# PIC32MX440F128L device description
Architecture: MIPS; Family: PIC32MX; Series: PIC32MX
Registers are 32-bit, read-write, no defined reset value unless marked. A register's access mark holds for its fields unless they carry their own. Offsets are from the block's base; [hi:lo] are bit positions; 'fields as' and 'values as' point back to an identical list.

## SPI
Instances: SPI 0x1f8057f4 in periph0
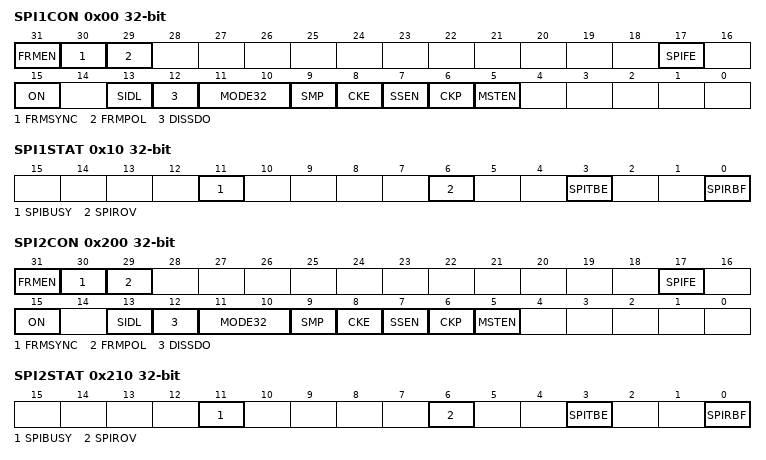
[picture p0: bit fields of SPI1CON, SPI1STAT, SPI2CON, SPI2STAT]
0x00 SPI1CON — SPI Control Register
  [31] FRMEN — Framed SPI Support bit
    1=Framed SPI support is enabled (SSx pin used as FSYNC input/output); 0=Framed SPI support is disabled
  [30] FRMSYNC — Frame Sync Pulse Direction Control on SSx pin bit (Framed SPI mode only)
    1=Frame sync pulse input (Slave mode); 0=Frame sync pulse output (Master mode)
  [29] FRMPOL — Frame Sync Polarity bit (Framed SPI mode only)
    1=Frame pulse is active-high; 0=Frame pulse is active-low
  [17] SPIFE — Frame Sync Pulse Edge Select bit
    1=Frame synchronization pulse coincides with the first bit clock; 0=Frame synchronization pulse precedes the first bit clock
  [15] ON — SPI Peripheral On bit
    1=SPI Peripheral is enabled; 0=SPI Peripheral is disabled
  [13] SIDL — Stop in Idle Mode bit
    1=Discontinue operation when CPU enters in Idle mode; 0=Continue operation in Idle mode
  [12] DISSDO — Disable SDOx pin bit
    1=SDOx pin is not used by the module. Pin is controlled by associated PORT register; 0=SDOx pin is controlled by the module
  [11:10] MODE32 — 32/16-Bit Communication Select bits
    3=(AUDEN=1) 24-bit Data, 32-bit FIFO, 32-bit Channel/64-bit Frame / (AUDEN=0) 32-bit communication; 2=(AUDEN=1) 32-bit Data, 32-bit FIFO, 32-bit Channel/64-bit Frame / (AUDEN=0) 32-bit communication; 1=(AUDEN=1) 16-bit Data, 16-bit FIFO, 32-bit Channel/64-bit Frame / (AUDEN=0) 16-bit communication; 0=(AUDEN=1) 16-bit Data, 16-bit FIFO, 16-bit Channel/32-bit Frame / (AUDEN=0) 8-bit communication
  [9] SMP — SPI Data Input Sample Phase bit (master mode only)
    1=(Master mode) Input data sampled at end of data output time / (Slave mode) value is ignored; 0=(Master mode) Input data sampled at middle of data output time / (Slave mode) value is ignored
  [8] CKE — SPI Clock Edge Select bit
    1=Serial output data changes on transition from active clock state to Idle clock state (see CKP bit); 0=Serial output data changes on transition from Idle clock state to active clock state (see CKP bit)
  [7] SSEN — Slave Select Enable bit
    1=SSx pin used for Slave mode; 0=SSx pin not used for Slave mode
  [6] CKP — Clock Polarity Select bit
    1=Idle state for clock is a high level; active state is a low level; 0=Idle state for clock is a low level; active state is a high level
  [5] MSTEN — Master Mode Enable bit
    1=Master mode; 0=Slave mode
0x10 SPI1STAT ro
  [11] SPIBUSY — SPI Activity Status bit
    1=SPI peripheral is currently busy with some transactions; 0=SPI peripheral is currently idle
  [6] SPIROV — Receive Overflow Flag bit
    1=A new data is completely received and discarded. The user software has not read the previous data in the SPIxBUF register.; 0=No overflow has occurred
  [3] SPITBE — SPI Transmit Buffer Empty Status bit
    1=Transmit buffer SPIxTXB is empty; 0=Transmit buffer SPIxTXB is not empty
  [0] SPIRBF — SPI Receive Buffer Full Status bit
    1=Receive buffer SPIxRXB is full; 0=Receive buffer SPIxRXB is not full
0x20 SPI1BUF
0x30 SPI1BRG
  [8:0] SPI1BRG
0x200 SPI2CON — SPI Control Register
  fields as SPI1CON
0x210 SPI2STAT ro
  fields as SPI1STAT
0x220 SPI2BUF
0x230 SPI2BRG
  [8:0] SPI2BRG

## TMR1
Instances: TMR1 0x1f8005f4 in periph0
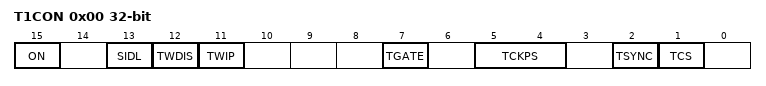
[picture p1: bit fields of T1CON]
0x00 T1CON — TYPE A TIMER CONTROL REGISTER
  [15] ON — Timer On bit
    1=Timer is enabled; 0=Timer is disabled
  [13] SIDL — Stop in Idle Mode bit
    1=Discontinue operation when device enters Idle mode; 0=Continue operation even in Idle mode
  [12] TWDIS — Asynchronous Timer Write Disable bit
    1=Writes to TMR1 are ignored until pending write operation completes; 0=Back-to-back writes are enabled (Legacy Asynchronous Timer functionality)
  [11] TWIP — Asynchronous Timer Write in Progress bit
    1=(In Asynchronous Timer mode) Asynchronous write to TMR1 register in progress / (in synchronous mode) read as 0; 0=(In Asynchronous Timer mode) Asynchronous write to TMR1 register complete / (in synchronous mode) read as 0
  [7] TGATE — Timer Gated Time Accumulation Enable bit
    1=(When TCS is 0) Gated time accumulation is enabled / (When TCS is 1) bit is ignored; 0=(When TCS is 0) Gated time accumulation is disabled / (When TCS is 1) bit is ignored
  [5:4] TCKPS — Timer Input Clock Prescale Select bits
    3=1:256 prescale value; 2=1:64 prescale value; 1=1:8 prescale value; 0=1:1 prescale value
  [2] TSYNC — Timer External Clock Input Synchronization Selection bit
    1=(When TCS is 1) External clock input is synchronized / (When TCS is 0) bit is ignored; 0=(When TCS is 1) External clock input is not synchronized / (When TCS is 0) bit is ignored
  [1] TCS — Timer Clock Source Select bit
    1=External clock from T1CKI pin; 0=Internal peripheral clock
0x10 TMR1
0x20 PR1

## TMR
Instances: TMR 0x1f8007f4 in periph0
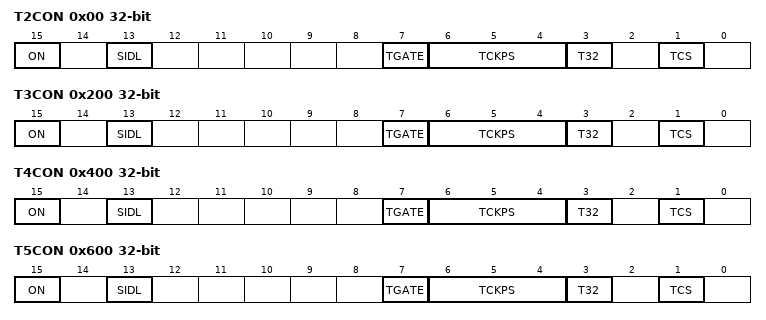
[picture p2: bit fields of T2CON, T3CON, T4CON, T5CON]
0x00 T2CON — Type B Timer Control Register
  [15] ON — Timer On bit
    1=Module is enabled; 0=Module is disabled
  [13] SIDL — Stop in Idle Mode bit
    1=Discontinue operation when device enters Idle mode; 0=Continue operation even in Idle mode
  [7] TGATE — Timer Gated Time Accumulation Enable bit
    1=(When TCS is 1): This bit is ignored and is read as 0 / (When TCS=0): Gated time accumulation is enabled; 0=(When TCS is 1): This bit is ignored and is read as 0 / (When TCS=0): Gated time accumulation is disabled
  [6:4] TCKPS — Timer Input Clock Prescale Select bits
    7=1:256 prescale value; 6=1:64 prescale value; 5=1:32 prescale value; 4=1:16 prescale value; 3=1:8 prescale value; 2=1:4 prescale value; 1=1:2 prescale value; 0=1:1 prescale value
  [3] T32 — 32-Bit Timer Mode Select bit
    1=Odd numbered and even numbered timers form a 32-bit timer; 0=Odd numbered and even numbered timers form separate 16-bit timers
  [1] TCS — Timer Clock Source Select bit
    1=External clock from TxCK pin; 0=Internal peripheral clock
0x10 TMR2
0x20 PR2
0x200 T3CON — Type B Timer Control Register
  fields as T2CON
0x210 TMR3
0x220 PR3
0x400 T4CON — Type B Timer Control Register
  fields as T2CON
0x410 TMR4
0x420 PR4
0x600 T5CON — Type B Timer Control Register
  fields as T2CON
0x610 TMR5
0x620 PR5

## WDT
Instances: WDT 0x1f800000 in periph0
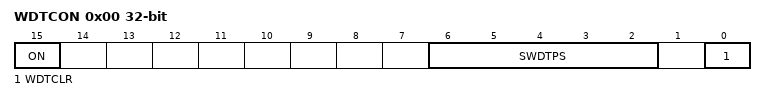
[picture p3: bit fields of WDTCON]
0x00 WDTCON
  [15] ON — Watchdog Timer Enable bit
    1=Enables the WDT if it is not enabled by the device configuration; 0=Disable the WDT if it was enabled in software
  [6:2] SWDTPS
  [0] WDTCLR — Watchdog Timer Reset bit
    1=Writing a 1 will clear the WDT; 0=Software cannot force this bit to a 0
